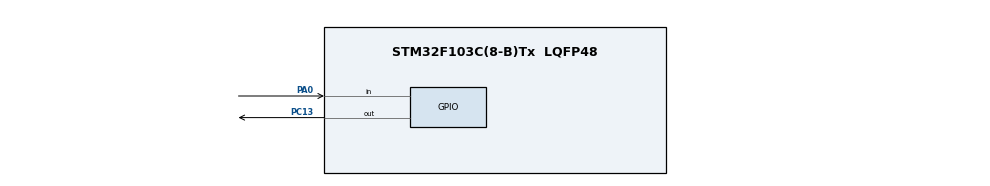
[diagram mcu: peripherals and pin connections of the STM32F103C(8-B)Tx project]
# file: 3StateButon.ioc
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Mcu.Family=STM32F1
Mcu.Name=STM32F103C(8-B)Tx
Mcu.Package=LQFP48
NVIC.PriorityGroup=NVIC_PRIORITYGROUP_4
PA0-WKUP.GPIO_PuPd=GPIO_PULLUP
PA0-WKUP.Signal=GPIO_Input
PA13.Mode=Serial_Wire
PA13.Signal=SYS_JTMS-SWDIO
PA14.Mode=Serial_Wire
PA14.Signal=SYS_JTCK-SWCLK
PC13-TAMPER-RTC.PinState=GPIO_PIN_RESET
PC13-TAMPER-RTC.Signal=GPIO_Output
ProjectManager.HeapSize=0x200
ProjectManager.StackSize=0x400
ProjectManager.TargetToolchain=MDK-ARM V5.32
RCC.APB1Freq_Value=8000000
RCC.APB2Freq_Value=8000000
board=custom

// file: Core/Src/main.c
/* USER CODE BEGIN Header */
/**
  ******************************************************************************
  * @file           : main.c
  * @brief          : Main program body
  ******************************************************************************
  * @attention
  *
  * Copyright (c) 2023 STMicroelectronics.
  * All rights reserved.
  *
  * This software is licensed under terms that can be found in the LICENSE file
  * in the root directory of this software component.
  * If no LICENSE file comes with this software, it is provided AS-IS.
  *
  ******************************************************************************
  */
/* USER CODE END Header */
#include "main.h"
#include "stm32f1xx_hal.h"
/* USER CODE BEGIN Includes */
#define DEBOUND_TIME 50
#define SINGLE_CLICK_TIME 1000
#define DOUBLE_CLICK_TIME 300

typedef enum
{
	NO_CLICK     = 0x00,
	SINGLE_CLICK = 0x01,
	DOUBLE_CLICK = 0x02,
	LONGCLICK_1S = 0x03
}BUTTON_STATE;
BUTTON_STATE Status;
/* USER CODE END Includes */

typedef struct {
	GPIO_TypeDef* BUTTON_PORT;
	uint16_t BUTTON_Pin;
	BUTTON_STATE State;
	uint16_t isPress;
	uint16_t timePress;
	uint16_t timeDouble;
}BUTTON_Name;
BUTTON_Name Button1;
/* USER CODE BEGIN PTD */
static uint8_t BUTTON_ReadPin(BUTTON_Name* Button)
{
	return HAL_GPIO_ReadPin(Button->BUTTON_PORT, Button->BUTTON_Pin);
}
static void BUTTON_DelayMs(uint16_t Time)
{
	HAL_Delay(Time);
}

// ************************** High Level Layer *****************************************************//
void BUTTON_Init(BUTTON_Name* Button, GPIO_TypeDef* BUTTON_PORT, uint16_t BUTTON_Pin)
{
	Button->BUTTON_PORT = BUTTON_PORT;
	Button->BUTTON_Pin = BUTTON_Pin;
}

BUTTON_STATE BUTTON_Read(BUTTON_Name* Button)
{
	Button->State = NO_CLICK;
	while(BUTTON_ReadPin(Button) == 0)
	{
		Button->timePress++;
		Button->isPress = 1;
		BUTTON_DelayMs(1);
	}
	if(Button->isPress)
	{
		while(BUTTON_ReadPin(Button) == 1)
		{
			Button->timeDouble++;
			BUTTON_DelayMs(1);
			if(Button->timeDouble > DOUBLE_CLICK_TIME)
			{
				if(Button->timePress > DEBOUND_TIME && Button->timePress <= SINGLE_CLICK_TIME)
				{
					Button->isPress = 0;
					Button->timePress = 0;
					Button->timeDouble = 0;
					Button->State = SINGLE_CLICK;
					return Button->State;
				}
				else if(Button->timePress  > SINGLE_CLICK_TIME)
				{
					Button->isPress = 0;
					Button->timePress = 0;
					Button->timeDouble = 0;
					Button->State = LONGCLICK_1S;
					return Button->State;
				}
			}
		}
		while(BUTTON_ReadPin(Button) == 0)
		{
			Button->State = DOUBLE_CLICK;
			Button->isPress = 0;
			Button->timePress = 0;
			Button->timeDouble = 0;
			return Button->State;
		}
	}
	return NO_CLICK;
}
/* USER CODE END PTD */

void SystemClock_Config(void);
static void MX_GPIO_Init(void);

int main(void)
{

  /* MCU Configuration--------------------------------------------------------*/

  /* Reset of all peripherals, Initializes the Flash interface and the Systick. */
  HAL_Init();

  /* Configure the system clock */
  SystemClock_Config();

  /* Initialize all configured peripherals */
  MX_GPIO_Init();
  /* USER CODE BEGIN 2 */
	BUTTON_Init(&Button1, GPIOA, GPIO_PIN_0);
	HAL_GPIO_WritePin(GPIOC,GPIO_PIN_13, 1);
  /* USER CODE END 2 */

  /* Infinite loop */
  while (1)
  {
	Status = BUTTON_Read(&Button1);
	if (Status == DOUBLE_CLICK)
	{
	HAL_GPIO_TogglePin (GPIOC, GPIO_PIN_13);
	HAL_Delay(200);
	HAL_GPIO_TogglePin (GPIOC, GPIO_PIN_13);
	HAL_Delay (200) ;
	HAL_GPIO_TogglePin (GPIOC, GPIO_PIN_13);
	HAL_Delay (200);
	HAL_GPIO_TogglePin (GPIOC, GPIO_PIN_13);
	HAL_Delay (200) ;
	HAL_GPIO_TogglePin (GPIOC, GPIO_PIN_13);
	HAL_Delay(200);
	HAL_GPIO_TogglePin (GPIOC, GPIO_PIN_13);
	HAL_Delay(200);
	HAL_GPIO_TogglePin (GPIOC, GPIO_PIN_13);
	HAL_Delay(200);
	HAL_GPIO_TogglePin (GPIOC, GPIO_PIN_13);
	HAL_Delay(200);
	Status = 0;
	}
	if (Status == SINGLE_CLICK)
	{
	HAL_GPIO_TogglePin(GPIOC, GPIO_PIN_13);
	Status = 0;
	}
   if (Status == LONGCLICK_1S)
	{
	HAL_GPIO_TogglePin (GPIOC, GPIO_PIN_13);
	HAL_Delay(1000);
	HAL_GPIO_TogglePin (GPIOC, GPIO_PIN_13);
	HAL_Delay (1000) ;
	HAL_GPIO_TogglePin (GPIOC, GPIO_PIN_13);
	HAL_Delay (1000);
	HAL_GPIO_TogglePin (GPIOC, GPIO_PIN_13);
	HAL_Delay (1000) ;
	HAL_GPIO_TogglePin (GPIOC, GPIO_PIN_13);
	HAL_Delay(1000);
	HAL_GPIO_TogglePin (GPIOC, GPIO_PIN_13);
	HAL_Delay(1000);
	HAL_GPIO_TogglePin (GPIOC, GPIO_PIN_13);
	HAL_Delay(1000);
	HAL_GPIO_TogglePin (GPIOC, GPIO_PIN_13);
	HAL_Delay(1000);
	Status = 0;
	}
  }
  /* USER CODE END 3 */
}

void SystemClock_Config(void)
{
  RCC_OscInitTypeDef RCC_OscInitStruct = {0};
  RCC_ClkInitTypeDef RCC_ClkInitStruct = {0};

  /** Initializes the RCC Oscillators according to the specified parameters
  * in the RCC_OscInitTypeDef structure.
  */
  RCC_OscInitStruct.OscillatorType = RCC_OSCILLATORTYPE_HSI;
  RCC_OscInitStruct.HSIState = RCC_HSI_ON;
  RCC_OscInitStruct.HSICalibrationValue = RCC_HSICALIBRATION_DEFAULT;
  RCC_OscInitStruct.PLL.PLLState = RCC_PLL_NONE;
  if (HAL_RCC_OscConfig(&RCC_OscInitStruct) != HAL_OK)
  {
    Error_Handler();
  }

  /** Initializes the CPU, AHB and APB buses clocks
  */
  RCC_ClkInitStruct.ClockType = RCC_CLOCKTYPE_HCLK|RCC_CLOCKTYPE_SYSCLK
                              |RCC_CLOCKTYPE_PCLK1|RCC_CLOCKTYPE_PCLK2;
  RCC_ClkInitStruct.SYSCLKSource = RCC_SYSCLKSOURCE_HSI;
  RCC_ClkInitStruct.AHBCLKDivider = RCC_SYSCLK_DIV1;
  RCC_ClkInitStruct.APB1CLKDivider = RCC_HCLK_DIV1;
  RCC_ClkInitStruct.APB2CLKDivider = RCC_HCLK_DIV1;

  if (HAL_RCC_ClockConfig(&RCC_ClkInitStruct, FLASH_LATENCY_0) != HAL_OK)
  {
    Error_Handler();
  }
}

static void MX_GPIO_Init(void)
{
  GPIO_InitTypeDef GPIO_InitStruct = {0};

  /* GPIO Ports Clock Enable */
  __HAL_RCC_GPIOC_CLK_ENABLE();
  __HAL_RCC_GPIOA_CLK_ENABLE();

  /*Configure GPIO pin Output Level */
  HAL_GPIO_WritePin(GPIOC, GPIO_PIN_13, GPIO_PIN_RESET);

  /*Configure GPIO pin : PC13 */
  GPIO_InitStruct.Pin = GPIO_PIN_13;
  GPIO_InitStruct.Mode = GPIO_MODE_OUTPUT_PP;
  GPIO_InitStruct.Pull = GPIO_NOPULL;
  GPIO_InitStruct.Speed = GPIO_SPEED_FREQ_LOW;
  HAL_GPIO_Init(GPIOC, &GPIO_InitStruct);

  /*Configure GPIO pin : PA0 */
  GPIO_InitStruct.Pin = GPIO_PIN_0;
  GPIO_InitStruct.Mode = GPIO_MODE_INPUT;
  GPIO_InitStruct.Pull = GPIO_PULLUP;
  HAL_GPIO_Init(GPIOA, &GPIO_InitStruct);

}

void Error_Handler(void)
{
  __disable_irq();
  while (1)
  {
  }
}
